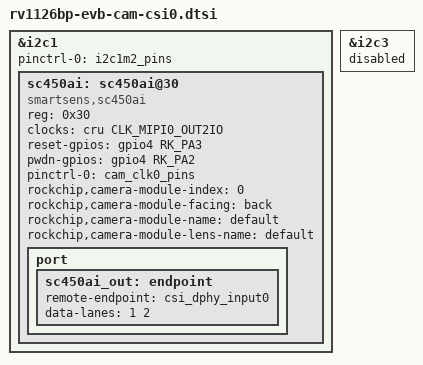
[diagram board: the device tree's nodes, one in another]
// SPDX-License-Identifier: (GPL-2.0+ OR MIT)
/*
 * Copyright (c) 2025 Rockchip Electronics Co., Ltd.
 *
 */
#include "rv1126b-evb-cam-csi0.dtsi"

&i2c1 {
	status = "okay";
	pinctrl-0 = <&i2c1m2_pins>;

	sc450ai: sc450ai@30 {
		compatible = "smartsens,sc450ai";
		status = "okay";
		reg = <0x30>;
		clocks = <&cru CLK_MIPI0_OUT2IO>;
		clock-names = "xvclk";
		reset-gpios = <&gpio4 RK_PA3 GPIO_ACTIVE_HIGH>;
		pwdn-gpios = <&gpio4 RK_PA2 GPIO_ACTIVE_HIGH>;
		pinctrl-names = "default";
		pinctrl-0 = <&cam_clk0_pins>;
		rockchip,camera-module-index = <0>;
		rockchip,camera-module-facing = "back";
		rockchip,camera-module-name = "default";
		rockchip,camera-module-lens-name = "default";
		port {
			sc450ai_out: endpoint {
				remote-endpoint = <&csi_dphy_input0>;
				data-lanes = <1 2>;
			};
		};
	};
};

&i2c3 {
	status = "disabled";
	/delete-node/ sc450ai@30;
};
